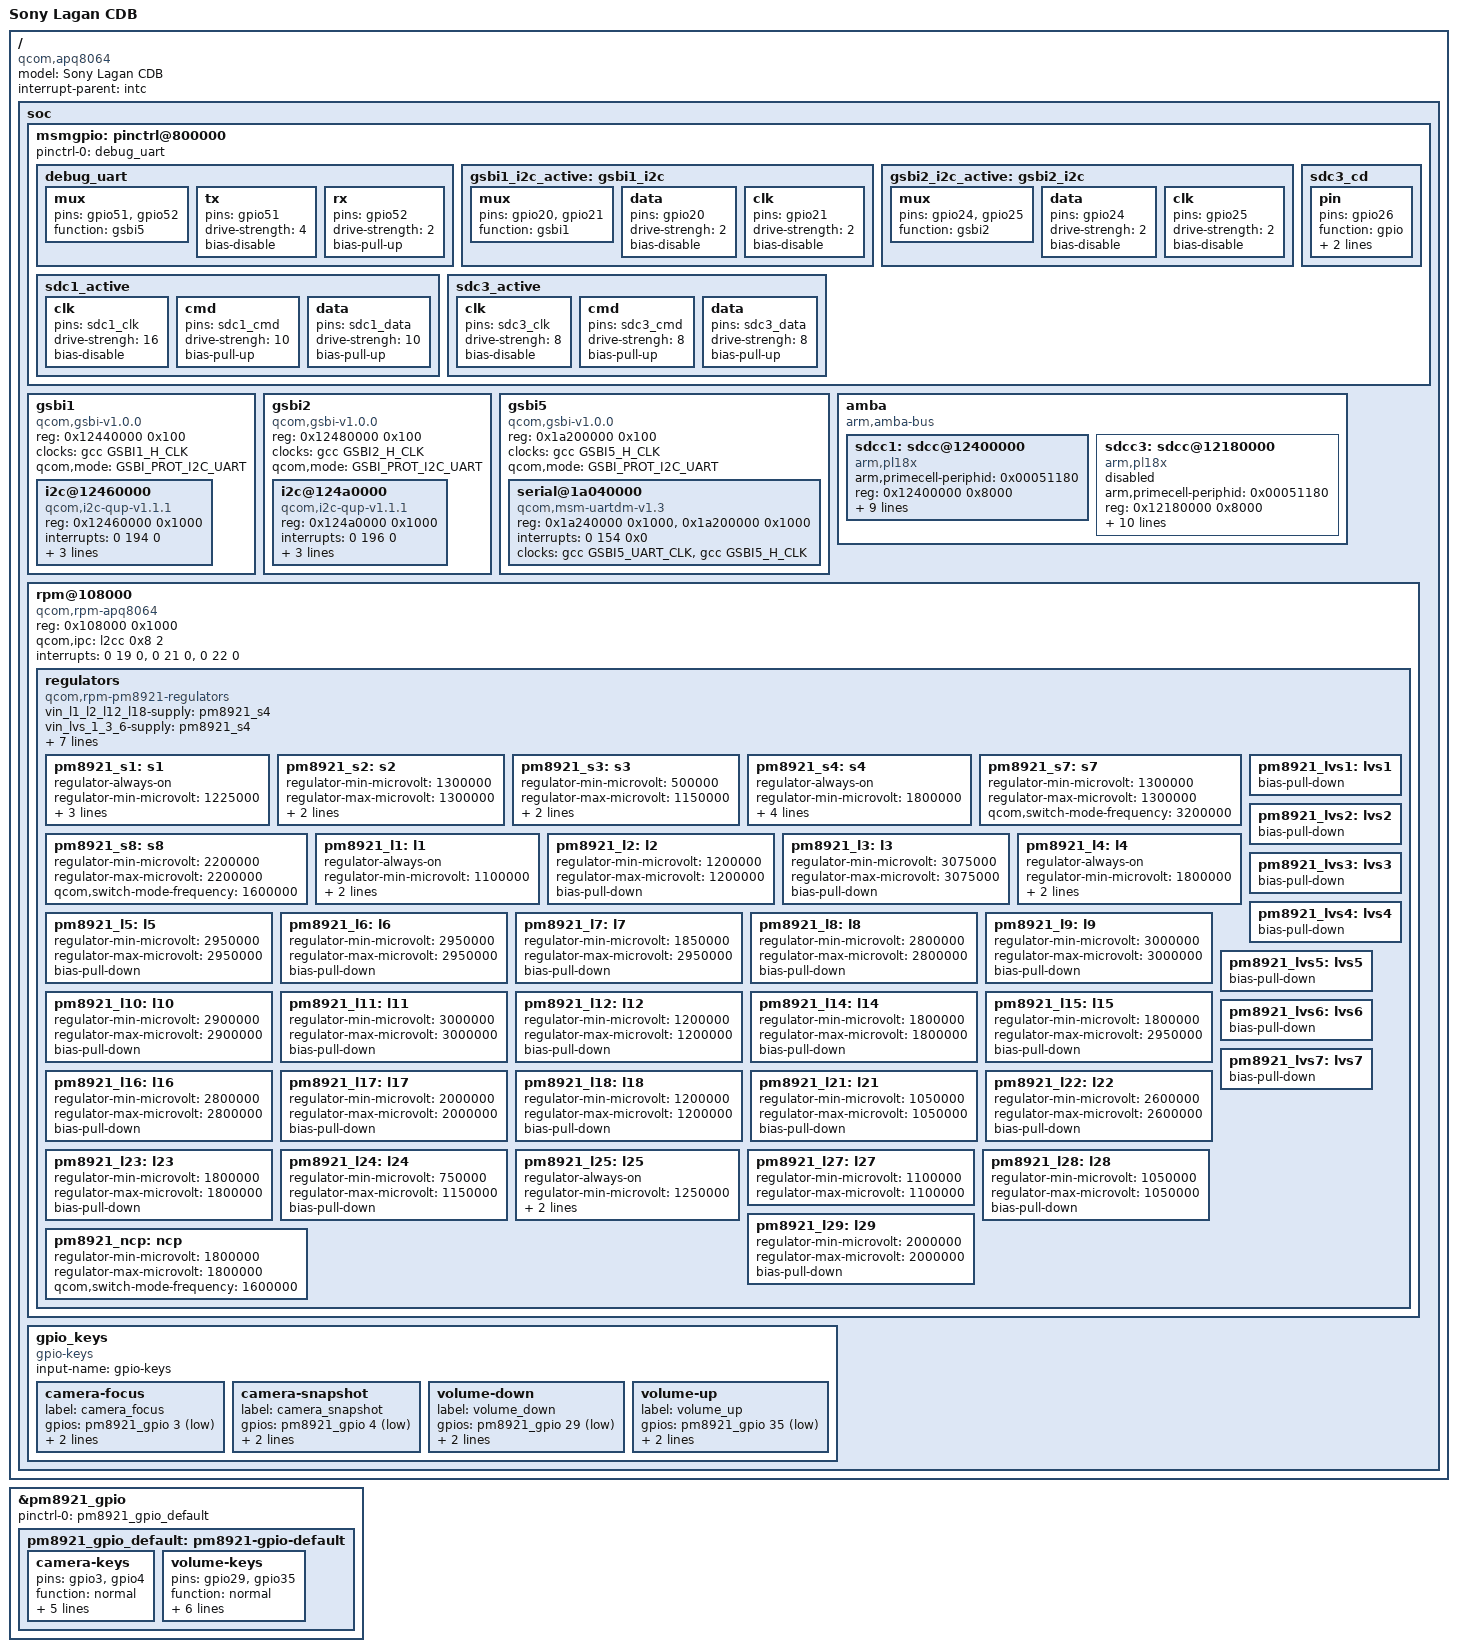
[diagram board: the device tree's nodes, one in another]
#include "qcom-apq8064.dtsi"
#include <dt-bindings/interrupt-controller/arm-gic.h>
#include <dt-bindings/soc/qcom,gsbi.h>

#include <dt-bindings/pinctrl/qcom,pmic-gpio.h>
#include <dt-bindings/mfd/qcom-rpm.h>
#include <dt-bindings/input/input.h>

/ {
	model = "Sony Lagan CDB";
	compatible = "qcom,apq8064";
	interrupt-parent = <&intc>;

	soc {
		msmgpio: pinctrl@800000 {
			pinctrl-names = "default";
			pinctrl-0 = <&debug_uart>;

			debug_uart: debug_uart {
				mux {
					pins = "gpio51", "gpio52";
					function = "gsbi5";
				};

				tx {
					pins = "gpio51";
					drive-strength = <4>;
					bias-disable;
				};

				rx {
					pins = "gpio52";
					drive-strength = <2>;
					bias-pull-up;
				};
			};

			gsbi1_i2c_active: gsbi1_i2c {
				mux {
					pins = "gpio20", "gpio21";
					function = "gsbi1";
				};

				data {
					pins = "gpio20";
					drive-strengh = <2>;
					bias-disable;
				};

				clk {
					pins = "gpio21";
					drive-strength = <2>;
					bias-disable;
				};
			};

			gsbi2_i2c_active: gsbi2_i2c {
				mux {
					pins = "gpio24", "gpio25";
					function = "gsbi2";
				};

				data {
					pins = "gpio24";
					drive-strengh = <2>;
					bias-disable;
				};

				clk {
					pins = "gpio25";
					drive-strength = <2>;
					bias-disable;
				};
			};

			sdc1_active: sdc1_active {
				clk {
					pins = "sdc1_clk";
					drive-strengh = <16>;
					bias-disable;
				};

				cmd {
					pins = "sdc1_cmd";
					drive-strengh = <10>;
					bias-pull-up;
				};

				data {
					pins = "sdc1_data";
					drive-strengh = <10>;
					bias-pull-up;
				};
			};

			sdc3_active: sdc3_active {
				clk {
					pins = "sdc3_clk";
					drive-strengh = <8>;
					bias-disable;
				};

				cmd {
					pins = "sdc3_cmd";
					drive-strengh = <8>;
					bias-pull-up;
				};

				data {
					pins = "sdc3_data";
					drive-strengh = <8>;
					bias-pull-up;
				};
			 };

			sdc3_cd: sdc3_cd {
				pin {
					pins = "gpio26";
					function = "gpio";

					drive-strength = <2>;
					bias-pull-up;
				};
			};
		};

		gsbi1 {
			compatible = "qcom,gsbi-v1.0.0";
			reg = <0x12440000 0x100>;
			clocks = <&gcc GSBI1_H_CLK>;
			clock-names = "iface";
			#address-cells = <1>;
			#size-cells = <1>;
			ranges;

			qcom,mode = <GSBI_PROT_I2C_UART>;

			i2c@12460000 {
				compatible = "qcom,i2c-qup-v1.1.1";
				reg = <0x12460000 0x1000>;
				interrupts = <0 194 0>;

				clocks = <&gcc GSBI1_QUP_CLK>, <&gcc GSBI1_H_CLK>;
				clock-names = "core", "iface";

				clock-frequency = <355000>;

				#address-cells = <1>;
				#size-cells = <0>;

				pinctrl-names = "default";
				pinctrl-0 = <&gsbi1_i2c_active>;
			};
		};

		gsbi2 {
			compatible = "qcom,gsbi-v1.0.0";
			reg = <0x12480000 0x100>;
			clocks = <&gcc GSBI2_H_CLK>;
			clock-names = "iface";
			#address-cells = <1>;
			#size-cells = <1>;
			ranges;

			qcom,mode = <GSBI_PROT_I2C_UART>;

			i2c@124a0000 {
				compatible = "qcom,i2c-qup-v1.1.1";
				reg = <0x124a0000 0x1000>;
				interrupts = <0 196 0>;

				clocks = <&gcc GSBI2_QUP_CLK>, <&gcc GSBI2_H_CLK>;
				clock-names = "core", "iface";

				clock-frequency = <355000>;

				#address-cells = <1>;
				#size-cells = <0>;

				pinctrl-names = "default";
				pinctrl-0 = <&gsbi2_i2c_active>;
			};
		};

		gsbi5 {
			compatible = "qcom,gsbi-v1.0.0";
			reg = <0x1a200000 0x100>;
			clocks = <&gcc GSBI5_H_CLK>;
			clock-names = "iface";
			#address-cells = <1>;
			#size-cells = <1>;
			ranges;

			qcom,mode = <GSBI_PROT_I2C_UART>;

			serial@1a040000 {
				compatible = "qcom,msm-uartdm-v1.3", "qcom,msm-uartdm";
				reg = <0x1a240000 0x1000>,
				      <0x1a200000 0x1000>;
				interrupts = <0 154 0x0>;
				clocks = <&gcc GSBI5_UART_CLK>, <&gcc GSBI5_H_CLK>;
				clock-names = "core", "iface";
			};
		};

		amba {
			compatible = "arm,amba-bus";
			#address-cells = <1>;
			#size-cells = <1>;
			ranges;

			sdcc1: sdcc@12400000 {
				compatible      = "arm,pl18x", "arm,primecell";
				arm,primecell-periphid = <0x00051180>;
				reg             = <0x12400000 0x8000>;
				interrupts      = <GIC_SPI 104 IRQ_TYPE_LEVEL_HIGH>;
				interrupt-names = "cmd_irq";
				clocks          = <&gcc SDC1_CLK>, <&gcc SDC1_H_CLK>;
				clock-names     = "mclk", "apb_pclk";
				bus-width       = <8>;
				max-frequency   = <192000000>;
				non-removable;
				cap-sd-highspeed;
				cap-mmc-highspeed;
				vmmc-supply = <&pm8921_l5>;

				pinctrl-names = "default";
				pinctrl-0 = <&sdc1_active>;

				status = "ok";
			};

			sdcc3: sdcc@12180000 {
				compatible      = "arm,pl18x", "arm,primecell";
				arm,primecell-periphid = <0x00051180>;
				status = "NO!";
				reg             = <0x12180000 0x8000>;
				interrupts      = <GIC_SPI 102 IRQ_TYPE_LEVEL_HIGH>;
				interrupt-names = "cmd_irq";
				clocks          = <&gcc SDC3_CLK>, <&gcc SDC3_H_CLK>;
				clock-names     = "mclk", "apb_pclk";
				bus-width       = <4>;
				cap-sd-highspeed;
				cap-mmc-highspeed;
				max-frequency   = <192000000>;
				no-1-8-v;
				vmmc-supply = <&pm8921_l6>;
				vqmmc-supply = <&pm8921_l7>;

				pinctrl-names = "default";
				pinctrl-0 = <&sdc3_active &sdc3_cd>;
			};
		};

		rpm@108000 {
                        compatible      = "qcom,rpm-apq8064";
                        reg             = <0x108000 0x1000>;
                        qcom,ipc        = <&l2cc 0x8 2>;

                        interrupts      = <0 19 0>, <0 21 0>, <0 22 0>;
                        interrupt-names = "ack", "err", "wakeup";

                        regulators {
				compatible = "qcom,rpm-pm8921-regulators";
				vin_l1_l2_l12_l18-supply = <&pm8921_s4>;
				vin_lvs_1_3_6-supply = <&pm8921_s4>;
				vin_lvs_4_5_7-supply = <&pm8921_s4>;
				vin_ncp-supply = <&pm8921_l6>;
				vin_lvs2-supply = <&pm8921_s4>;
				vin_l24-supply = <&pm8921_s1>;
				vin_l25-supply = <&pm8921_s1>;
				vin_l27-supply = <&pm8921_s7>;
				vin_l28-supply = <&pm8921_s7>;

                                /* Buck SMPS */
                                pm8921_s1: s1 {
                                        regulator-always-on;
                                        regulator-min-microvolt = <1225000>;
                                        regulator-max-microvolt = <1225000>;
                                        qcom,switch-mode-frequency = <3200000>;
                                        bias-pull-down;
                                };

                                pm8921_s2: s2 {
                                        regulator-min-microvolt = <1300000>;
                                        regulator-max-microvolt = <1300000>;
                                        qcom,switch-mode-frequency = <1600000>;
                                        bias-pull-down;
                                };

                                pm8921_s3: s3 {
                                        regulator-min-microvolt = <500000>;
                                        regulator-max-microvolt = <1150000>;
                                        qcom,switch-mode-frequency = <4800000>;
                                        bias-pull-down;
                                };

                                pm8921_s4: s4 {
                                        regulator-always-on;
                                        regulator-min-microvolt = <1800000>;
                                        regulator-max-microvolt = <1800000>;
                                        qcom,switch-mode-frequency = <1600000>;
                                        bias-pull-down;
                                        qcom,force-mode = <QCOM_RPM_FORCE_MODE_AUTO>;
                                };

                                pm8921_s7: s7 {
                                        regulator-min-microvolt = <1300000>;
                                        regulator-max-microvolt = <1300000>;
                                        qcom,switch-mode-frequency = <3200000>;
                                };

                                pm8921_s8: s8 {
                                        regulator-min-microvolt = <2200000>;
                                        regulator-max-microvolt = <2200000>;
                                        qcom,switch-mode-frequency = <1600000>;
                                };

                                /* PMOS LDO */
                                pm8921_l1: l1 {
                                        regulator-always-on;
                                        regulator-min-microvolt = <1100000>;
                                        regulator-max-microvolt = <1100000>;
                                        bias-pull-down;
                                };

                                pm8921_l2: l2 {
                                        regulator-min-microvolt = <1200000>;
                                        regulator-max-microvolt = <1200000>;
                                        bias-pull-down;
                                };

                                pm8921_l3: l3 {
                                        regulator-min-microvolt = <3075000>;
                                        regulator-max-microvolt = <3075000>;
                                        bias-pull-down;
                                };

                                pm8921_l4: l4 {
                                        regulator-always-on;
                                        regulator-min-microvolt = <1800000>;
                                        regulator-max-microvolt = <1800000>;
                                        bias-pull-down;
                                };

                                pm8921_l5: l5 {
                                        regulator-min-microvolt = <2950000>;
                                        regulator-max-microvolt = <2950000>;
                                        bias-pull-down;
                                };

                                pm8921_l6: l6 {
                                        regulator-min-microvolt = <2950000>;
                                        regulator-max-microvolt = <2950000>;
                                        bias-pull-down;
                                };

                                pm8921_l7: l7 {
                                        regulator-min-microvolt = <1850000>;
                                        regulator-max-microvolt = <2950000>;
                                        bias-pull-down;
                                };

                                pm8921_l8: l8 {
                                        regulator-min-microvolt = <2800000>;
                                        regulator-max-microvolt = <2800000>;
                                        bias-pull-down;
                                };

                                pm8921_l9: l9 {
                                        regulator-min-microvolt = <3000000>;
                                        regulator-max-microvolt = <3000000>;
                                        bias-pull-down;
                                };

                                pm8921_l10: l10 {
                                        regulator-min-microvolt = <2900000>;
                                        regulator-max-microvolt = <2900000>;
                                        bias-pull-down;
                                };

                                pm8921_l11: l11 {
                                        regulator-min-microvolt = <3000000>;
                                        regulator-max-microvolt = <3000000>;
                                        bias-pull-down;
                                };

                                pm8921_l12: l12 {
                                        regulator-min-microvolt = <1200000>;
                                        regulator-max-microvolt = <1200000>;
                                        bias-pull-down;
                                };

                                pm8921_l14: l14 {
                                        regulator-min-microvolt = <1800000>;
                                        regulator-max-microvolt = <1800000>;
                                        bias-pull-down;
                                };

                                pm8921_l15: l15 {
                                        regulator-min-microvolt = <1800000>;
                                        regulator-max-microvolt = <2950000>;
                                        bias-pull-down;
                                };

                                pm8921_l16: l16 {
                                        regulator-min-microvolt = <2800000>;
                                        regulator-max-microvolt = <2800000>;
                                        bias-pull-down;
                                };

                                pm8921_l17: l17 {
                                        regulator-min-microvolt = <2000000>;
                                        regulator-max-microvolt = <2000000>;
                                        bias-pull-down;
                                };

                                pm8921_l18: l18 {
                                        regulator-min-microvolt = <1200000>;
                                        regulator-max-microvolt = <1200000>;
                                        bias-pull-down;
                                };

                                pm8921_l21: l21 {
                                        regulator-min-microvolt = <1050000>;
                                        regulator-max-microvolt = <1050000>;
                                        bias-pull-down;
                                };

                                pm8921_l22: l22 {
                                        regulator-min-microvolt = <2600000>;
                                        regulator-max-microvolt = <2600000>;
                                        bias-pull-down;
                                };

                                pm8921_l23: l23 {
                                        regulator-min-microvolt = <1800000>;
                                        regulator-max-microvolt = <1800000>;
                                        bias-pull-down;
                                };

                                pm8921_l24: l24 {
                                        regulator-min-microvolt = <750000>;
                                        regulator-max-microvolt = <1150000>;
                                        bias-pull-down;
                                };

                                pm8921_l25: l25 {
                                        regulator-always-on;
                                        regulator-min-microvolt = <1250000>;
                                        regulator-max-microvolt = <1250000>;
                                        bias-pull-down;
                                };

                                pm8921_l27: l27 {
                                        regulator-min-microvolt = <1100000>;
                                        regulator-max-microvolt = <1100000>;
                                };

                                pm8921_l28: l28 {
                                        regulator-min-microvolt = <1050000>;
                                        regulator-max-microvolt = <1050000>;
                                        bias-pull-down;
                                };

                                pm8921_l29: l29 {
                                        regulator-min-microvolt = <2000000>;
                                        regulator-max-microvolt = <2000000>;
                                        bias-pull-down;
                                };

                                /* Low Voltage Switch */
                                pm8921_lvs1: lvs1 {
                                        bias-pull-down;
                                };

                                pm8921_lvs2: lvs2 {
                                        bias-pull-down;
                                };

                                pm8921_lvs3: lvs3 {
                                        bias-pull-down;
                                };

                                pm8921_lvs4: lvs4 {
                                        bias-pull-down;
                                };

                                pm8921_lvs5: lvs5 {
                                        bias-pull-down;
                                };

                                pm8921_lvs6: lvs6 {
                                        bias-pull-down;
                                };

                                pm8921_lvs7: lvs7 {
                                        bias-pull-down;
                                };

                                pm8921_ncp: ncp {
                                        regulator-min-microvolt = <1800000>;
                                        regulator-max-microvolt = <1800000>;
                                        qcom,switch-mode-frequency = <1600000>;
                                };
                        };
                };

		gpio_keys {
			compatible = "gpio-keys";
			input-name = "gpio-keys";

			camera-focus {
				label = "camera_focus";
				gpios = <&pm8921_gpio 3 1>;
				linux,input-type = <1>;
				linux,code = <KEY_CAMERA_FOCUS>;
			};

			camera-snapshot {
				label = "camera_snapshot";
				gpios = <&pm8921_gpio 4 1>;
				linux,input-type = <1>;
				linux,code = <KEY_CAMERA>;
			};

			volume-down {
				label = "volume_down";
				gpios = <&pm8921_gpio 29 1>;
				linux,input-type = <1>;
				linux,code = <KEY_VOLUMEDOWN>;
			};

			volume-up {
				label = "volume_up";
				gpios = <&pm8921_gpio 35 1>;
				linux,input-type = <1>;
				linux,code = <KEY_VOLUMEUP>;
			};
		};
	};
};

&pm8921_gpio {
	pinctrl-0 = <&pm8921_gpio_default>;
	pinctrl-names = "default";

	pm8921_gpio_default: pm8921-gpio-default {
		camera-keys {
			pins = "gpio3", "gpio4";
			function = "normal";

			bias-pull-up;
			input-enable;
			drive-push-pull;
			qcom,drive-strength = <PMIC_GPIO_STRENGTH_NO>;
			power-source = <2>;
		};

		volume-keys {
			pins = "gpio29", "gpio35";
			function = "normal";

			bias-pull-up;
			qcom,pull-up-strength = <0>;
			input-enable;
			drive-push-pull;
			qcom,drive-strength = <PMIC_GPIO_STRENGTH_NO>;
			power-source = <2>;
		};
	};
};
